# apollo5b register map
Vendor: Ambiq Micro; Series: Apollo; File version: 1.0
CPU: CM55 r1p1, little endian, MPU, FPU, double-precision FPU, DSP, I-cache, D-cache, VTOR, ITCM, DTCM, 4 interrupt priority bits, 0 interrupts, 8 SAU regions
Registers are 32-bit, read-write, reset 0x0 unless marked. A register's access mark holds for its fields unless they carry their own. Offsets are from the block's base; [hi:lo] are bit positions; {n}, {i} and the like mark numbered series; 'fields as' and 'values as' point back to an identical list.

## MSPI0 — Multi-bit SPI Master
Base 0x40060000
Same registers: MSPI1 0x40061000, MSPI2 0x40062000, MSPI3 0x40063000
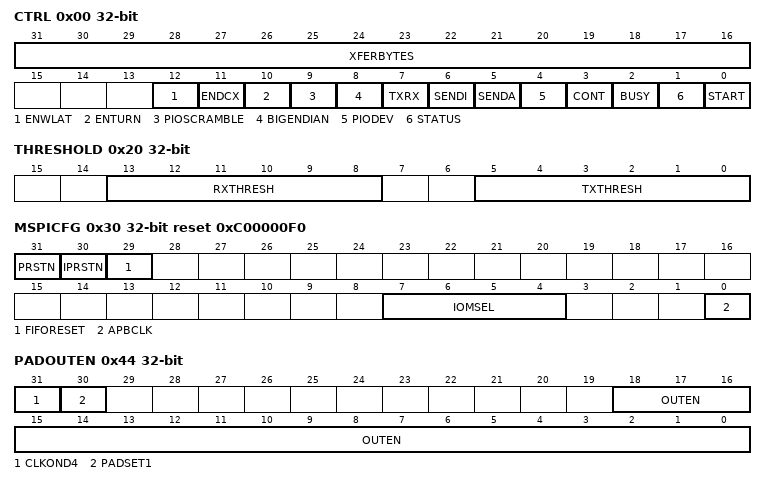
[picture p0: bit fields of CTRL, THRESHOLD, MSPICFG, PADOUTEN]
0x00 CTRL — This register is used to enable individual PIO based transactions to a device on the bus. The CFG register must be programmed properly for the transfer, and the ADDR and INSTR registers should be programmed if the SENDI and SENDA fields are enabled.
  [31:16] XFERBYTES — Number of bytes to transmit or receive (based on TXRX bit)
  [12] ENWLAT — Enable Write Latency Counter (time between address and first data byte). Counter value is WRITELATENCY.
  [11] ENDCX — Enable DCX signal on data [1]
  [10] ENTURN — Indicates whether TX->RX turnaround cycles should be enabled for this operation (see TURNAROUND field in CFG register).
  [9] PIOSCRAMBLE — Enables data scrambling for PIO opertions. This should only be used for data operations and never for commands to a device.
  [8] BIGENDIAN — 1 indicates data in FIFO is in big endian format (MSB first); 0 indicates little endian data (default, LSB first).
  [7] TXRX — 1 Indicates a TX operation, 0 indicates an RX operation of XFERBYTES
  [6] SENDI — Indicates whether an instruction phase should be sent (see INSTR field and ISIZE field in CFG register)
  [5] SENDA — Indicates whether an address phase should be sent (see ADDR register and ASIZE field in CFG register)
  [4] PIODEV — Selects the Device configutation to use for PIO requests
    0=DEVICE0 (Use DEVICE0 Configuration); 1=DEVICE1 (Use DEVICE1 CONFIGURATION)
  [3] CONT — Continuation transfer. When 1, indicates that the MSPI will hold CE low after the transaction completes. This is included for compatibility with IOM module since the MSPI transfer module can handle most cases in a single transfer. NOTE: CONT functionality only works with CLKDIV=2 (24 MHz).
  [2] BUSY — Command status: 1 indicates controller is busy (command in progress)
  [1] STATUS — Command status: 1 indicates command has completed. Cleared by writing 1 to this bit or starting a new transfer.
  [0] START — Write to 1 to initiate a PIO transaction on the bus (typically the entire register should be written at once with this bit set).
0x04 CTRL1 — These registers are used to enable individual PIO based transactions to a device on the bus. The CFG register must be programmed properly for the transfer, and the ADDR and INSTR registers should be programmed if the SENDI and SENDA fields are enabled.
  [3:0] PIOMIXED — Provides override controls for data operations where instruction, address, and data may transfer in different rates.
    0=NORMAL (Transfers all proceed using the settings in DEVCFG register (everything in the same data rate)); 1=D2 (Data operations proceed in dual data rate); 3=AD2 (Address and Data operations proceed in dual data rate); 5=D4 (Data operations proceed in quad data rate); 7=AD4 (Address and Data operations proceed in quad data rate); 9=D8 (Data operations proceed in octal data rate); 11=AD8 (Address and Data operations proceed in octal data rate)
0x08 ADDR — Optional Address field to send for PIO transfers
  [31:0] ADDR — Optional Address field to send (after optional instruction field) - qualified by ASIZE in CMD register. NOTE: This register is aliased to DMADEVADDR.
0x0C INSTR — Optional Instruction field to send for PIO transfers
  [15:0] INSTR — Optional Instruction field to send (1st byte) - qualified by ISEND/ISIZE
0x10 TXFIFO — TX Data FIFO
  [31:0] TXFIFO — Data to be transmitted. Data should normally be aligned to the LSB (pad the upper bits with zeros) unless BIGENDIAN is set.
0x14 RXFIFO — RX Data FIFO
  [31:0] RXFIFO — Receive data. Data is aligned to the LSB (padded zeros on upper bits) unless BIGENDIAN is set.
0x18 TXENTRIES — Number of words in TX FIFO
  [5:0] TXENTRIES — Number of 32-bit words/entries in TX FIFO
0x1C RXENTRIES — Number of words in RX FIFO
  [5:0] RXENTRIES — Number of 32-bit words/entries in RX FIFO
0x20 THRESHOLD — Threshold levels that trigger RXFull and TXEmpty interrupts
  [13:8] RXTHRESH — Number of entries in TX FIFO that cause RXE interrupt
  [5:0] TXTHRESH — Number of entries in TX FIFO that cause TXF interrupt
0x30 MSPICFG reset 0xC00000F0 — Timing configuration bits for the MSPI module. PRSTN, IPRSTN, and FIFORESET can be used to reset portions of the MSPI interface in order to clear error conditions. The remaining bits control clock frequency and TX/RX capture timings.
  [31] PRSTN — Peripheral reset. Master reset to the entire MSPI module (DMA, XIP, and transfer state machines). 1=normal operation, 0=in reset.
  [30] IPRSTN — IP block reset. Write to 0 to put the transfer module in reset or 1 for normal operation. This may be required after error conditions to clear the transfer on the bus.
  [29] FIFORESET — Reset MSPI FIFO (active high). 1=reset FIFO, 0=normal operation. May be used to manually flush the FIFO in error handling.
  [7:4] IOMSEL — Selects which IOM is selected for CQ handshake status.
    {v}=IOM{v} (ERROR: desc VALUE MISSING) (v=0..7); {v}=MSPI{v-8} (ERROR: desc VALUE MISSING) (v=8..11); 15=DISABLED (No IOM selected. Signals always zero.)
  [0] APBCLK — Enable continuous APB clock. For power-efficient operation, APBCLK should be set to 0.
    0=DIS (Disable continuous clock.); 1=EN (Enable continuous clock.)
0x44 PADOUTEN — Enable bits for the MSPI output pads. Each active MSPI line should be set to 1 in the OUTEN field below.
  [31] CLKOND4 — Output clock on MSPI data[4]
  [30] PADSET1 — Only applicable on mspi1. When set, use gpio95 .. gpio 104 as the pads. This extra set of pads is to run mspi0 on HEX and mspi1 concurrently. Note that the timing of this extra pads may not be as good as the origianl pads.
  [18:0] OUTEN — Output pad enable configuration. Indicates which pads should be driven. Bits [3:0] are Quad0 data. Bits [7:4] are Quad1 data. Bit [8] is clock. Bit [9] is BM/DQS. Bit [10:17] are data for 16-bit. Bit[18] is BM/DQS for 16-bit.
    0x10F=QUAD0 (Quad0 (4 data + 1 clock)); 0x1F0=QUAD1 (Quad1 (4 data + 1 clock)); 0x3FF=OCTAL (Octal (8 data + 1 clock)); 0x103=SERIAL0 (Serial (2 data + 1 clock)); 0x130=SERIAL1 (Serial (2 data + 1 clock)); 0x7FFFF=HEX (Octal (16 data + 1 clock + 2 bytemask))
0x48 PADOVEREN — Enables PIO-like pad override control
  [18:0] OVERRIDEEN — Output pad override enable. Bit mask for pad outputs. When set to 1, the values in the OVERRIDE field are driven on the pad (output enable is implicitly set in this mode). [7:0]=data[7:0] [8]=clock [9]=DM [18:11]=data[15:8]
0x4C PADOVER — Override data value
  [18:0] OVERRIDE — Output pad override value. [7:0]=data [8]=clock [9]=DM
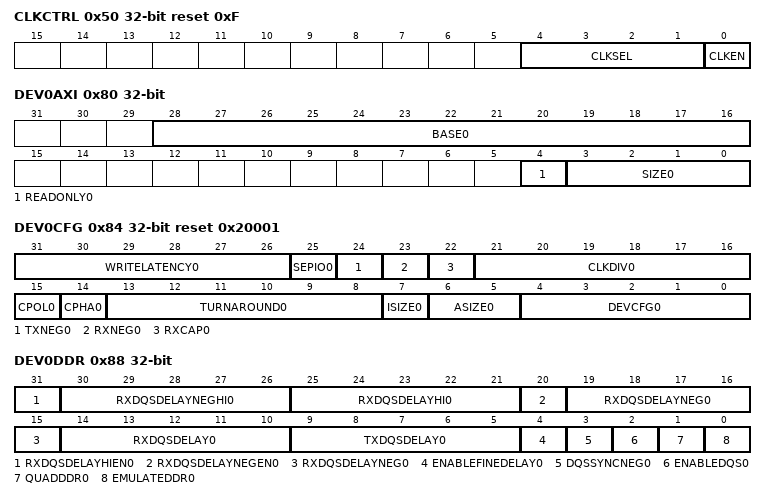
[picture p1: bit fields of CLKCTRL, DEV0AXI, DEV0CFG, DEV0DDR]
0x50 CLKCTRL reset 0xF — Clock control
  [4:1] CLKSEL — MSPI io Clock select
    0=HFRC_750KHz (750KHz sourced from the HFRC); 1=HFRC_1p5MHz (1.5MHz sourced from the HFRC); 2=HFRC_3MHz (3MHz sourced from the HFRC); 3=HFRC_6MHz (6MHz sourced from the HFRC); 4=HFRC_12MHz (12MHz sourced from the HFRC); 5=HFRC_24MHz (24MHz sourced from the HFRC); 6=HFRC_48MHz (48MHz sourced from the HFRC); 7=HFRC_96MHz (96MHz sourced from the HFRC); 8=HFRC_192MHz (192MHz sourced from the HFRC); 9=HFRC2_125MHz (125MHz sourced from the HFRC2); 10=HFRC2_250MHz (250MHz sourced from the HFRC2)
  [0] CLKEN — MSPI io Clock enable.
    0=DIS (Disable mspi io clock); 1=EN (Enable mspi io clock)
0x80 DEV0AXI — Specifies the base address and aperture range of the device as mapped onto the AXI bus
  [28:16] BASE0 — XIPEN has to be enabled to enable aperture. The BASE address needs to be SIZE aligned.
  [4] READONLY0 — Indicates the AXI aperture is read-only
    1=READONLY (Indicates AXI aperture only supports read operations); 0=READWRITE (Indicates AXI aperture supports read and write operations)
  [3:0] SIZE0 — Indicates the AXI aperture size
    0=SIZE64K (64KB Aperture); 1=SIZE128K (128KB Aperture); 2=SIZE256K (256KB Aperture); 3=SIZE512K (512KB Aperture); 4=SIZE1M (1MB Aperture); 5=SIZE2M (2MB Aperture); 6=SIZE4M (4MB Aperture); 7=SIZE8M (8MB Aperture); 8=SIZE16M (16MB Aperture); 9=SIZE32M (32MB Aperture); 10=SIZE64M (64MB Aperture); 11=SIZE128M (128MB Aperture); 12=SIZE256M (256MB Aperture); 13=SIZE512M (512MB Aperture)
0x84 DEV0CFG reset 0x20001 — Command formatting for PIO based transactions (initiated by writes to CTRL register)
  [31:26] WRITELATENCY0 — Number of write Latency cycles. Qualified by ENTURN bit field.
  [25] SEPIO0 — Separate IO configuration. This bit should be set when the target device has separate MOSI and MISO pins. Respective IN/OUT bits below should be set to map pins.
  [24] TXNEG0 — Launches TX data a half clock cycle (~10ns) early. This should normally be programmed to zero (NORMAL).
    0=NORMAL (TX launched from posedge internal clock); 1=NEGEDGE (TX data launched from negedge of internal clock)
  [23] RXNEG0 — Adjusts the RX capture phase to the negedge of the 48MHz internal clock (~10ns early). For normal operation, it is expected that RXNEG will be set to 0.
    0=NORMAL (RX data sampled on posedge of internal clock); 1=NEGEDGE (RX data sampled on negedge of internal clock)
  [22] RXCAP0 — Controls RX data capture phase. A setting of 0 (NORMAL) captures read data at the normal capture point relative to the internal clock launch point. However, to accomodate chip/pad/board delays, a setting of RXCAP of 1 is expected to be used to align the capture point with the return data window. This bit is used in conjunction with RXNEG to provide 4 unique capture points, all about 10ns apart.
    0=NORMAL (RX Capture phase aligns with CPHA setting); 1=DELAY (RX Capture phase is delayed from CPHA setting by one clock edge)
  [21:16] CLKDIV0 — Clock Divider. Allows dividing main MSPI core clock (125MHz/96MHz) by integer multiples. Enumerations are provided for common frequency, but any integer divide from 96 MHz is allowed. Odd divide ratios will result in a 33/66 percent duty cycle with a long low clock pulse (to allow longer round-trip for read data).
    {v}=CLKDIV{v} (Core Clock dividied by {v}) (v=1..4); 6=CLKDIV6 (Core Clock dividied by 6); 8=CLKDIV8 (Core Clock dividied by 8); 12=CLKDIV12 (Core Clock dividied by 12); 16=CLKDIV16 (Core Clock dividied by 16); 24=CLKDIV24 (Core Clock dividied by 24); 32=CLKDIV32 (Core Clock dividied by 32)
  [15] CPOL0 — Serial clock polarity.
    0=LOW (Clock inactive state is low.); 1=HIGH (Clock inactive state is high.)
  [14] CPHA0 — Serial clock phase.
    0=MIDDLE (Clock toggles in middle of data bit.); 1=START (Clock toggles at start of data bit.)
  [13:8] TURNAROUND0 — Number of turnaound cycles (for TX->RX transitions). Qualified by ENTURN bit field.
  [7] ISIZE0 — Instruction Size
    0=I8 (Instruction is 1 byte); 1=I16 (Instruction is 2 bytes)
  [6:5] ASIZE0 — Address Size. Address bytes to send from ADDR register
    0=A1 (Send one address byte); 1=A2 (Send two address bytes); 2=A3 (Send three address bytes); 3=A4 (Send four address bytes)
  [4:0] DEVCFG0 — Flash configuration for XIP and AUTO DMA operations. Controls value for SER (Slave Enable) for XIP operations and address generation for DMA/XIP modes. Also used to configure SPIFRF (frame format).
    1=SERIAL0 (Single bit SPI flash on chip select 0); 2=SERIAL1 (Single bit SPI flash on chip select 1); 5=DUAL0 (Dual SPI flash on chip select 0); 6=DUAL1 (Dual bit SPI flash on chip select 1); 9=QUAD0 (Quad SPI flash on chip select 0); 10=QUAD1 (Quad SPI flash on chip select 1); 13=OCTAL0 (Octal SPI flash on chip select 0); 14=OCTAL1 (Octal SPI flash on chip select 1); 15=QUADPAIRED (Dual Quad SPI flash on chip selects 0/1.); 3=QUADPAIRED_SERIAL (Dual Quad SPI flash on chip selects 0/1, but transmit in serial mode for initialization operations); 17=HEX0 (Hex SPI flash on chip selects 0.); 18=HEX1 (Hex SPI flash on chip selects 1.)
0x88 DEV0DDR — Timing configuration bits for DDR operation of the MSPI module.
  [31] RXDQSDELAYHIEN0 — When 1, RXDQSDELAYHI and RXDQSDELAYNEGHI is used for falling edge of the clock.
  [30:26] RXDQSDELAYNEGHI0 — This acts as an offset to the computed value (should be set to 0 by default) of falling edge for 2nd DQS on HEX mode.
  [25:21] RXDQSDELAYHI0 — This acts as an offset to the computed value (should be set to 0 by default) for 2nd DQS on HEX mode.
  [20] RXDQSDELAYNEGEN0 — When 1, RXDQSDELAYNEG is used for falling edge of the clock.
  [19:15] RXDQSDELAYNEG0 — This acts as an offset to the computed value (should be set to 0 by default) of falling edge.
  [14:10] RXDQSDELAY0 — This acts as an offset to the computed value (should be set to 0 by default)
  [9:5] TXDQSDELAY0 — This acts as an offset to the computed value (should be set to 0 by default)
  [4] ENABLEFINEDELAY0 — Enables use of delay line to provide fine control over traditional RX capture clock.
  [3] DQSSYNCNEG0 — Use negative edge of clock for DDR data sync
  [2] ENABLEDQS0 — In EMULATEDDR mode, enable DQS for read capture
  [1] QUADDDR0 — Deprecated. No effect on RevC.
  [0] EMULATEDDR0 — Drive external clock at 1/2 rate to emulate DDR mode
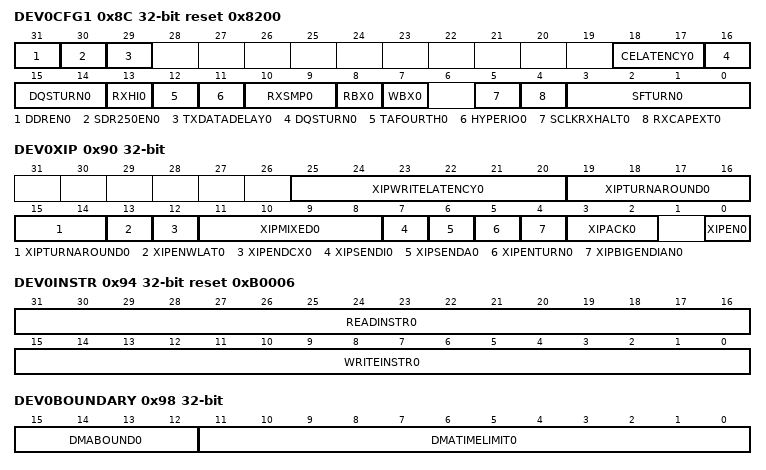
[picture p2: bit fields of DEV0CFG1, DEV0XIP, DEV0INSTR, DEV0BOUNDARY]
0x8C DEV0CFG1 reset 0x8200 — Timing and mode configuration bits for the MSPI module.
  [31] DDREN0 — New DDR mode/logic enable
  [30] SDR250EN0 — Enable MSPI core logic to run at the same frequency as its input clock. This bit has no effect when DDREN is 1
  [29] TXDATADELAY0 — Delay TXDATA output by 1 clock cycle
  [18:17] CELATENCY0 — Mem CE assertion latency before the first Mem transfer clock
    0=NORMAL (1 clock cycle before first mem transfer clock); 1=ADD1 (2 clock cycles before first mem transfer clock); 2=ADD2 (3 clock cycles before first mem transfer clock); 3=ADD3 (4 clock cycles before first mem transfer clock)
  [16:14] DQSTURN0 — In DQS mode, the internal cycle count to enable DQS path.
  [13] RXHI0 — Force st_rx to start at clock high of mspi_clk
  [12] TAFOURTH0 — Add 1/4th mspi_clk in DDR to turnaround. Recommended set this to 1 when EMULATEDDR is set in non-DQS mode (ENABLEDQS = 0).
  [11] HYPERIO0 — When using Windbond, set this bit to 1 to generate CA[47:0] in hardware.
  [10:9] RXSMP0 — Sampling edge based on sclk edge. No effect when div1
  [8] RBX0 — Enable the support of RBX ( page boundary crossing on read )
  [7] WBX0 — Enable the support of WBX ( page boundary crossing on write )
  [5] SCLKRXHALT0 — Halt sclk based on xfer_count
  [4] RXCAPEXT0 — Specify the number of apb_clk of RX capture phse {RXCAPEXT, RXCAP}
  [3:0] SFTURN0 — Subtract from internal counter of write latency and turnaround
0x90 DEV0XIP — When any SPI flash is configured, this register must be properly programmed before XIP or AUTO DMA operations commence.
  [25:20] XIPWRITELATENCY0 — Number of write Latency cycles. Qualified by XIPENWLAT bit field.
  [19:14] XIPTURNAROUND0 — Number of turnaound cycles (for TX->RX transitions). Qualified by XIPENTURN bit field.
  [13] XIPENWLAT0 — Enable Write Latency counter for XIP write transactions
  [12] XIPENDCX0 — Enable DCX signal on data [1] for XIP/DMA operations
  [11:8] XIPMIXED0 — Provides override controls for data operations where instruction, address, and data may transfer in different rates.
    values as CTRL1.PIOMIXED
  [7] XIPSENDI0 — Indicates whether XIP/AUTO DMA operations should send an instruction (see READINSTR field and ISIZE field in CFG)
  [6] XIPSENDA0 — Indicates whether XIP/AUTO DMA operations should send an an address phase (see DMADEVADDR register and ASIZE field in CFG)
  [5] XIPENTURN0 — Indicates whether XIP/AUTO DMA operations should enable TX->RX turnaround cycles
  [4] XIPBIGENDIAN0 — Indicates whether XIP/AUTO DMA data transfers are in big or little endian format
  [3:2] XIPACK0 — Controls transmission of Micron XIP acknowledge cycles (Micron Flash devices only)
    0=NOACK (No acknowledege sent. Data IOs are tristated the first turnaround cycle); 2=ACK (Positive acknowledege sent. Data IOs are driven to 0 the first turnaround cycle to acknowledge XIP mode); 3=TERMINATE (Negative acknowledege sent. Data IOs are driven to 1 the first turnaround cycle to terminate XIP mode. XIPSENDI should be reenabled for the next transfer)
  [0] XIPEN0 — Enable the XIP (eXecute In Place) function which effectively enables the address decoding of the MSPI device in the flash/cache address space at address 0x04000000-0x07FFFFFF.
0x94 DEV0INSTR reset 0xB0006 — When any SPI flash is configured, this register must be properly programmed before XIP or AUTO DMA operations commence.
  [31:16] READINSTR0 — Read command sent to flash for DMA/XIP operations
  [15:0] WRITEINSTR0 — Write command sent for DMA operations
0x98 DEV0BOUNDARY — Allows large transfers to be broken up into smaller ones in hardware to accommodate needs of external devices and allow XIP/XIPMM. Only applicable for memory-mapped devices (PSRAM, Flash, etc) where address can be retransmitted without side effects.
  [15:12] DMABOUND0 — DMA Address boundary
    0=NONE (Disable DMA address boundary breaks); 1=BREAK32 (Break at 32 byte boundary (0x20 increments)); 2=BREAK64 (Break at 64 byte boundary (0x40 increments)); 3=BREAK128 (Break at 128 byte boundary (0x80 increments)); 4=BREAK256 (Break at 256 byte boundary (0x100 increments)); 5=BREAK512 (Break at 512 byte boundary (0x200 increments)); 6=BREAK1K (Break at 1KB boundary (0x400 increments)); 7=BREAK2K (Break at 2KB boundary (0x800 increments)); 8=BREAK4K (Break at 4KB boundary (0x1000 increments)); 9=BREAK8K (Break at 8KB boundary (0x2000 increments)); 10=BREAK16K (Break at 16KB boundary (0x4000 increments))
  [11:0] DMATIMELIMIT0 — DMA time limit. Can be used to limit the transaction time on the MSPI bus. The count is in ~100 ns increments for the 96 MHz clock input. A value of 0 disables the counter.
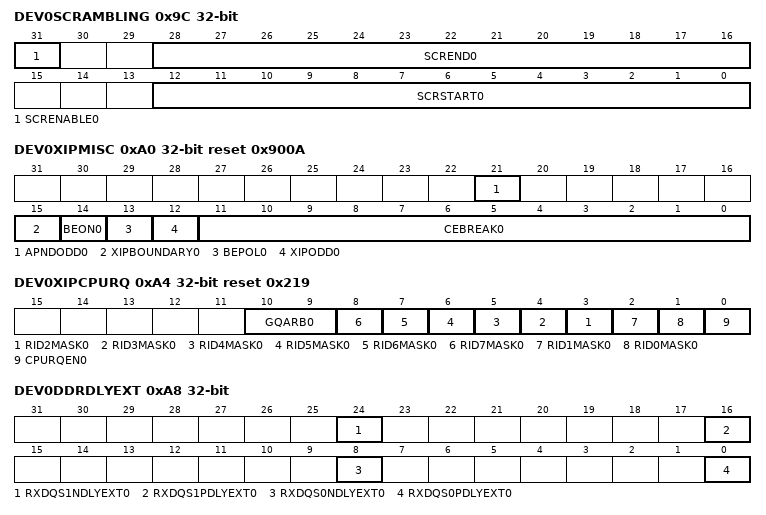
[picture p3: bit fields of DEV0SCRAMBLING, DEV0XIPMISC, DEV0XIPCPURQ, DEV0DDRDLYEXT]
0x9C DEV0SCRAMBLING — Enables data scrambling for the specified range external flash addresses. Scrambling does not impact flash access performance.
  [31] SCRENABLE0 — Enables Data Scrambling Region. When 1 reads and writes to the range will be scrambled. When 0, data will be read/written unmodified. Address range is specified in 64K granularity and the START/END ranges are included within the range.
  [28:16] SCREND0 — Scrambling region end address [28:16] (64K block granularity). The END block is the LAST block included in the scrambled address range.
  [12:0] SCRSTART0 — Scrambling region start address [28:16] (64K block granularity). The START block is the FIRST block included in the scrambled address range.
0xA0 DEV0XIPMISC reset 0x900A — Miscellaneous XIP control registers for AXI logic
  [21] APNDODD0 — Append dummy byte to odd number of write
    0=DIS (No appending byte); 1=EN (Append one dummy byte)
  [15] XIPBOUNDARY0 — Deprecated. No effect on RevC.
    0=DIS (ERROR: desc VALUE MISSING); 1=EN (ERROR: desc VALUE MISSING)
  [14] BEON0 — Byte enable always on for all lanes
    0=DIS (Byte enable is calculated on the fly); 1=EN (Byte enable of all bytes are always on)
  [13] BEPOL0 — byte mask polarity to MSPI xfer
  [12] XIPODD0 — Convert odd starting address to word-aligned starting address with byte-enables for holes. For example, an AXI transaction with wstrb of 0x0600 results in mspi transaction of addr=8 and BE=0b1001 ( active low ).
    0=DIS (No conversion); 1=EN (Enable the conversion)
  [11:0] CEBREAK0 — Number of clock cycles for CE deassertion time
0xA4 DEV0XIPCPURQ reset 0x219 — XIP CPU Read Queue Configuration for AXI logic
  [10:9] GQARB0 — Arbitration Bias between General (Non-CPU) and CPU Rd Queue
    0=B0 (1:1 Simple round robin access grant); 1=B1 (2:1 access grant to General:CPU queue); 2=B2 (3:1 access grant to General:CPU queue); 3=B3 (4:1 access grant to General:CPU queue)
  [n+1] RID{n}MASK0 (n=2..7) — CPU Read ID {n} will in included in CPU Read Queue (if CPURQEN=1)
  [2] RID1MASK0 — CPU Read ID 1 will in included in CPU Read Queue (if CPURQEN=1) (Invalid for CM55 system)
  [1] RID0MASK0 — CPU Read ID 0 will in included in CPU Read Queue (if CPURQEN=1) (Invalid for CM55 system)
  [0] CPURQEN0 — Enable CPU Read Queue
    0=DIS (CPU Read Queue is disabled); 1=EN (CPU Read Queue is enabled)
0xA8 DEV0DDRDLYEXT — DDR RX DQS Delayline MSB bits extenstion for DEV0DDR
  [24] RXDQS1NDLYEXT0 — MSB extension to DEV0DDR.RXDQSDELAYNEGHI0
  [16] RXDQS1PDLYEXT0 — MSB extension to DEV0DDR.RXDQSDELAYHI0
  [8] RXDQS0NDLYEXT0 — MSB extension to DEV0DDR.RXDQSDELAYNEG0
  [0] RXDQS0PDLYEXT0 — MSB extension to DEV0DDR.RXDQSDELAY0
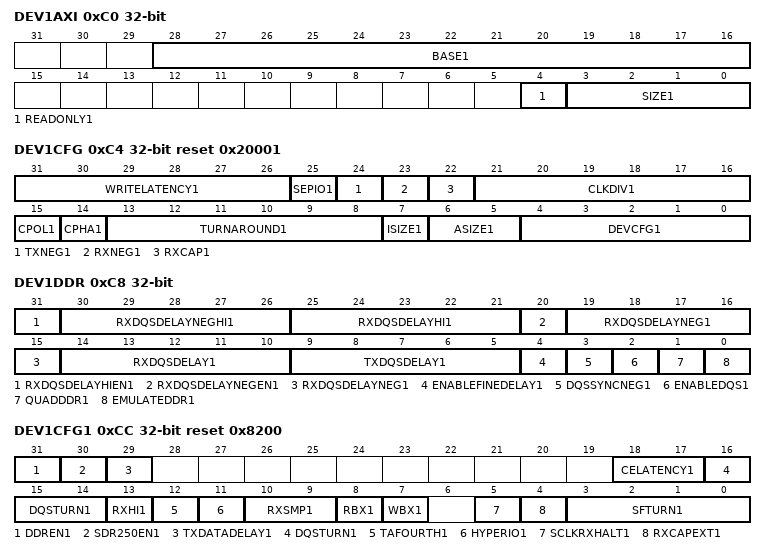
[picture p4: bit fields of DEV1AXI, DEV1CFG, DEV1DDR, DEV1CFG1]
0xC0 DEV1AXI — Specifies the base address and aperture range of the device as mapped onto the AXI bus
  [28:16] BASE1 — XIPEN has to be enabled to enable aperture. The BASE address needs to be SIZE aligned.
  [4] READONLY1 — Indicates the AXI aperture is read-only
    values as DEV0AXI.READONLY0
  [3:0] SIZE1 — Indicates the AXI aperture size
    values as DEV0AXI.SIZE0
0xC4 DEV1CFG reset 0x20001 — Command formatting for PIO based transactions (initiated by writes to CTRL register)
  [31:26] WRITELATENCY1 — Number of write Latency cycles. Qualified by ENTURN bit field.
  [25] SEPIO1 — Separate IO configuration. This bit should be set when the target device has separate MOSI and MISO pins. Respective IN/OUT bits below should be set to map pins.
  [24] TXNEG1 — Launches TX data a half clock cycle (~10ns) early. This should normally be programmed to zero (NORMAL).
    values as DEV0CFG.TXNEG0
  [23] RXNEG1 — Adjusts the RX capture phase to the negedge of the 48MHz internal clock (~10ns early). For normal operation, it is expected that RXNEG will be set to 0.
    values as DEV0CFG.RXNEG0
  [22] RXCAP1 — Controls RX data capture phase. A setting of 0 (NORMAL) captures read data at the normal capture point relative to the internal clock launch point. However, to accomodate chip/pad/board delays, a setting of RXCAP of 1 is expected to be used to align the capture point with the return data window. This bit is used in conjunction with RXNEG to provide 4 unique capture points, all about 10ns apart.
    values as DEV0CFG.RXCAP0
  [21:16] CLKDIV1 — Clock Divider. Allows dividing main MSPI core clock (125MHz/96MHz) by integer multiples. Enumerations are provided for common frequency, but any integer divide from 96 MHz is allowed. Odd divide ratios will result in a 33/66 percent duty cycle with a long low clock pulse (to allow longer round-trip for read data).
    {v}=CLKDIV{v} (Core Clock dividied by {v}) (v=1..4); 6=CLKDIV6 (Core Clock dividied by 6); 8=CLKDIV8 (Core Clock dividied by 8); 12=Core Clock dividied by 12; 16=Core Clock dividied by 16; 24=CLKDIV24 (Core Clock dividied by 24); 32=CLKDIV32 (Core Clock dividied by 32)
  [15] CPOL1 — Serial clock polarity.
    values as DEV0CFG.CPOL0
  [14] CPHA1 — Serial clock phase.
    values as DEV0CFG.CPHA0
  [13:8] TURNAROUND1 — Number of turnaound cycles (for TX->RX transitions). Qualified by ENTURN bit field.
  [7] ISIZE1 — Instruction Size
    0=I8 (Instruction is 1 byte); 1=I16 (Instruction is 2 bytes)
  [6:5] ASIZE1 — Address Size. Address bytes to send from ADDR register
    values as DEV0CFG.ASIZE0
  [4:0] DEVCFG1 — Flash configuration for XIP and AUTO DMA operations. Controls value for SER (Slave Enable) for XIP operations and address generation for DMA/XIP modes. Also used to configure SPIFRF (frame format).
    values as DEV0CFG.DEVCFG0
0xC8 DEV1DDR — Timing configuration bits for DDR operation of the MSPI module.
  [31] RXDQSDELAYHIEN1 — When 1, RXDQSDELAYHI and RXDQSDELAYNEGHI is used for falling edge of the clock.
  [30:26] RXDQSDELAYNEGHI1 — This acts as an offset to the computed value (should be set to 0 by default) of falling edge for 2nd DQS on HEX mode.
  [25:21] RXDQSDELAYHI1 — This acts as an offset to the computed value (should be set to 0 by default) for 2nd DQS on HEX mode.
  [20] RXDQSDELAYNEGEN1 — When 1, RXDQSDELAYNEG is used for falling edge of the clock.
  [19:15] RXDQSDELAYNEG1 — This acts as an offset to the computed value (should be set to 0 by default) of falling edge.
  [14:10] RXDQSDELAY1 — This acts as an offset to the computed value (should be set to 0 by default)
  [9:5] TXDQSDELAY1 — This acts as an offset to the computed value (should be set to 0 by default)
  [4] ENABLEFINEDELAY1 — Enables use of delay line to provide fine control over traditional RX capture clock.
  [3] DQSSYNCNEG1 — Use negative edge of clock for DDR data sync
  [2] ENABLEDQS1 — In EMULATEDDR mode, enable DQS for read capture
  [1] QUADDDR1 — Deprecated. No effect on RevC.
  [0] EMULATEDDR1 — Drive external clock at 1/2 rate to emulate DDR mode
0xCC DEV1CFG1 reset 0x8200 — Timing and mode configuration bits for the MSPI module.
  [31] DDREN1 — New DDR mode/logic enable
  [30] SDR250EN1 — Enable MSPI core logic to run at the same frequency as its input clock. This bit has no effect when DDREN is 1
  [29] TXDATADELAY1 — Delay TXDATA output by 1 clock cycle
  [18:17] CELATENCY1 — Mem CE assertion latency before the first Mem transfer clock
    values as DEV0CFG1.CELATENCY0
  [16:14] DQSTURN1 — In DQS mode, the internal cycle count to enable DQS path.
  [13] RXHI1 — Force st_rx to start at clock high of mspi_clk
  [12] TAFOURTH1 — Add 1/4th mspi_clk in DDR to turnaround. Recommended set this to 1 when EMULATEDDR is set in non-DQS mode (ENABLEDQS = 0).
  [11] HYPERIO1 — When using Windbond, set this bit to 1 to generate CA[47:0] in hardware.
  [10:9] RXSMP1 — Sampling edge based on sclk edge. No effect when div1
  [8] RBX1 — Enable the support of RBX ( page boundary crossing on read )
  [7] WBX1 — Enable the support of WBX ( page boundary crossing on write )
  [5] SCLKRXHALT1 — Halt sclk based on xfer_count
  [4] RXCAPEXT1 — Specify the number of apb_clk of RX capture phse {RXCAPEXT, RXCAP}
  [3:0] SFTURN1 — Subtract from internal counter of write latency and turnaround
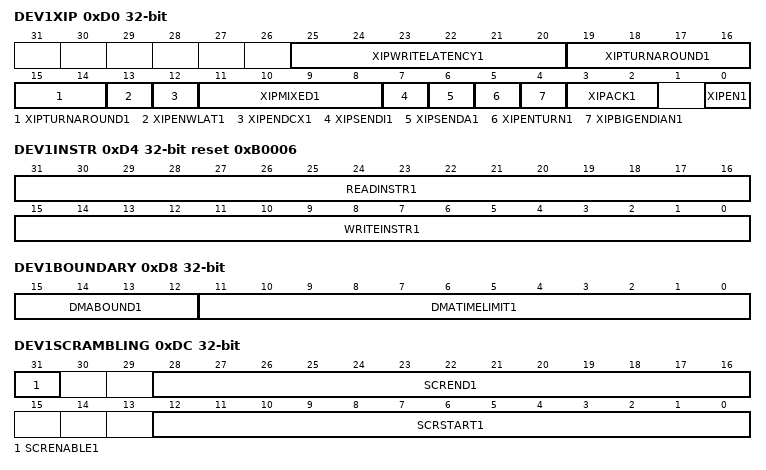
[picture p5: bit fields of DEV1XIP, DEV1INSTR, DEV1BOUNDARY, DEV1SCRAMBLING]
0xD0 DEV1XIP — When any SPI flash is configured, this register must be properly programmed before XIP or AUTO DMA operations commence.
  [25:20] XIPWRITELATENCY1 — Number of write Latency cycles. Qualified by XIPENWLAT bit field.
  [19:14] XIPTURNAROUND1 — Number of turnaound cycles (for TX->RX transitions). Qualified by XIPENTURN bit field.
  [13] XIPENWLAT1 — Enable Write Latency counter for XIP write transactions
  [12] XIPENDCX1 — Enable DCX signal on data [1] for XIP/DMA operations
  [11:8] XIPMIXED1 — Provides override controls for data operations where instruction, address, and data may transfer in different rates.
    values as CTRL1.PIOMIXED
  [7] XIPSENDI1 — Indicates whether XIP/AUTO DMA operations should send an instruction (see READINSTR field and ISIZE field in CFG)
  [6] XIPSENDA1 — Indicates whether XIP/AUTO DMA operations should send an an address phase (see DMADEVADDR register and ASIZE field in CFG)
  [5] XIPENTURN1 — Indicates whether XIP/AUTO DMA operations should enable TX->RX turnaround cycles
  [4] XIPBIGENDIAN1 — Indicates whether XIP/AUTO DMA data transfers are in big or little endian format
  [3:2] XIPACK1 — Controls transmission of Micron XIP acknowledge cycles (Micron Flash devices only)
    values as DEV0XIP.XIPACK0
  [0] XIPEN1 — Enable the XIP (eXecute In Place) function which effectively enables the address decoding of the MSPI device in the flash/cache address space at address 0x04000000-0x07FFFFFF.
0xD4 DEV1INSTR reset 0xB0006 — When any SPI flash is configured, this register must be properly programmed before XIP or AUTO DMA operations commence.
  [31:16] READINSTR1 — Read command sent to flash for DMA/XIP operations
  [15:0] WRITEINSTR1 — Write command sent for DMA operations
0xD8 DEV1BOUNDARY — Allows large transfers to be broken up into smaller ones in hardware to accommodate needs of external devices and allow XIP/XIPMM. Only applicable for memory-mapped devices (PSRAM, Flash, etc) where address can be retransmitted without side effects.
  [15:12] DMABOUND1 — DMA Address boundary
    values as DEV0BOUNDARY.DMABOUND0
  [11:0] DMATIMELIMIT1 — DMA time limit. Can be used to limit the transaction time on the MSPI bus. The count is in ~100 ns increments for the 96 MHz clock input. A value of 0 disables the counter.
0xDC DEV1SCRAMBLING — Enables data scrambling for the specified range external flash addresses. Scrambling does not impact flash access performance.
  [31] SCRENABLE1 — Enables Data Scrambling Region. When 1 reads and writes to the range will be scrambled. When 0, data will be read/written unmodified. Address range is specified in 64K granularity and the START/END ranges are included within the range.
  [28:16] SCREND1 — Scrambling region end address [28:16] (64K block granularity). The END block is the LAST block included in the scrambled address range.
  [12:0] SCRSTART1 — Scrambling region start address [28:16] (64K block granularity). The START block is the FIRST block included in the scrambled address range.
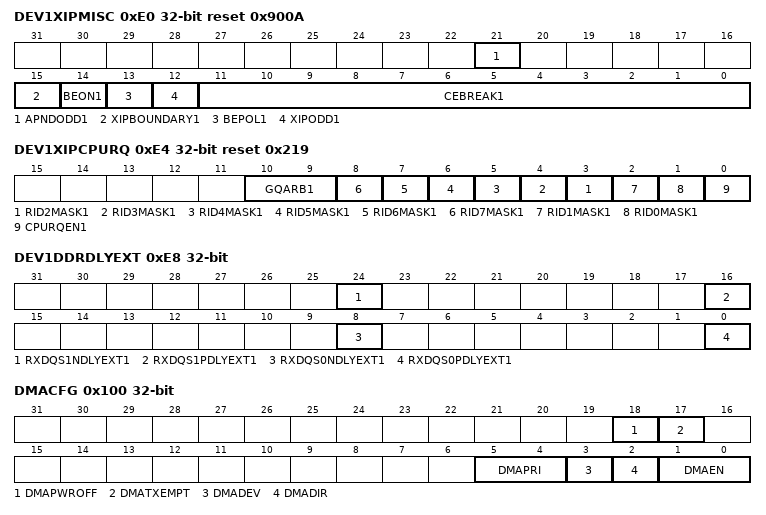
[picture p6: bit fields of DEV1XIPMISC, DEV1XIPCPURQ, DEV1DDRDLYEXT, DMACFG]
0xE0 DEV1XIPMISC reset 0x900A — Miscellaneous XIP control registers for AXI logic
  [21] APNDODD1 — Append dummy byte to odd number of write
    0=DIS (No appending byte); 1=EN (Append one dummy byte)
  [15] XIPBOUNDARY1 — Deprecated. No effect on RevC.
    values as DEV0XIPMISC.XIPBOUNDARY0
  [14] BEON1 — Byte enable always on for all lanes
    values as DEV0XIPMISC.BEON0
  [13] BEPOL1 — byte mask polarity to MSPI xfer
  [12] XIPODD1 — Convert odd starting address to word-aligned starting address with byte-enables for holes. For example, an AXI transaction with wstrb of 0x0600 results in mspi transaction of addr=8 and BE=0b1001 ( active low ).
    0=DIS (No conversion); 1=EN (Enable the conversion)
  [11:0] CEBREAK1 — Number of clock cycles for CE deassertion time
0xE4 DEV1XIPCPURQ reset 0x219 — XIP CPU Read Queue Configuration for AXI logic
  [10:9] GQARB1 — Arbitration Bias between General (Non-CPU) and CPU Rd Queue
    values as DEV0XIPCPURQ.GQARB0
  [n+1] RID{n}MASK1 (n=2..7) — CPU Read ID {n} will in included in CPU Read Queue (if CPURQEN=1)
  [2] RID1MASK1 — CPU Read ID 1 will in included in CPU Read Queue (if CPURQEN=1) (Invalid for CM55 system)
  [1] RID0MASK1 — CPU Read ID 0 will in included in CPU Read Queue (if CPURQEN=1) (Invalid for CM55 system)
  [0] CPURQEN1 — Enable CPU Read Queue
    values as DEV0XIPCPURQ.CPURQEN0
0xE8 DEV1DDRDLYEXT — DDR RX DQS Delayline MSB bits extenstion for DEV1DDR
  [24] RXDQS1NDLYEXT1 — MSB extension to DEV1DDR.RXDQSDELAYNEGHI1
  [16] RXDQS1PDLYEXT1 — MSB extension to DEV1DDR.RXDQSDELAYHI1
  [8] RXDQS0NDLYEXT1 — MSB extension to DEV1DDR.RXDQSDELAYNEG1
  [0] RXDQS0PDLYEXT1 — MSB extension to DEV1DDR.RXDQSDELAY1
0x100 DMACFG — DMA Configuration
  [18] DMAPWROFF — Power off MSPI domain upon completion of DMA operation.
  [17] DMATXEMPT — For DMA_M2P, only start when DMA fifo is not empty.
  [5:4] DMAPRI — Sets the Priority of the DMA request
    0=LOW (Low Priority (service as best effort)); 1=HIGH (High Priority (service immediately)); 2=AUTO (Auto Priority (priority raised once TX FIFO empties or RX FIFO fills))
  [3] DMADEV — DMA Device Select
    0=DEV0 (Select Device 0 for DMA); 1=DEV1 (Select Device 1 for DMA)
  [2] DMADIR — Direction
    0=P2M (Peripheral to Memory (SRAM) transaction); 1=M2P (Memory to Peripheral transaction)
  [1:0] DMAEN — DMA Enable. Setting this bit to EN will start the DMA operation
    0=DIS (Disable DMA Function); 3=EN (Enable HW controlled DMA Function to manage DMA to flash devices. HW will automatically handle issuance of instruction/address bytes based on settings in the FLASH register.)
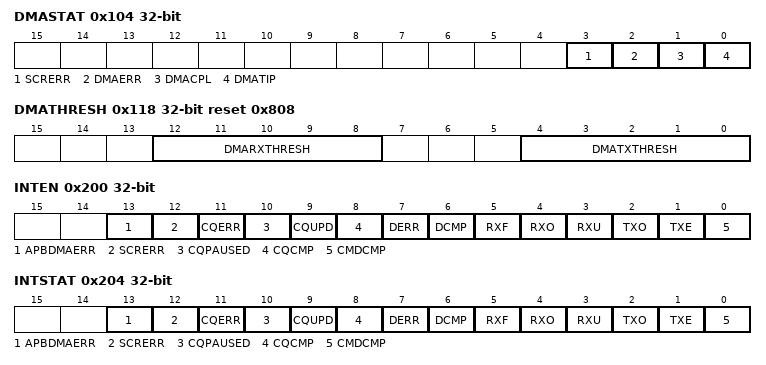
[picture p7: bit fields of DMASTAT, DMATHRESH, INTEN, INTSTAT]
0x104 DMASTAT — DMA Status
  [3] SCRERR — Scrambling Access Alignment Error. This active high bit signals that a scrambling operation was specified for a non-word aligned DEVADDR.
  [2] DMAERR — DMA Error. This active high bit signals that an error was encountered during the DMA operation.
  [1] DMACPL — DMA Transfer Complete. This signals the end of the DMA operation.
  [0] DMATIP — DMA Transfer In Progress indicator. 1 will indicate that a DMA transfer is active. The DMA transfer may be waiting on data, transferring data, or waiting for priority. All of these will be indicated with a 1. A 0 will indicate that the DMA is fully complete and no further transactions will be done.
0x108 DMATARGADDR — DMA Target Address
  [31:0] TARGADDR — Target byte address for source of DMA (either read or write). In cases of non-word aligned addresses, the DMA logic will take care for ensuring only the target bytes are read/written.
0x10C DMADEVADDR — DMA Device Address
  [31:0] DEVADDR — SPI Device address for automated DMA transactions (both read and write).
0x110 DMATOTCOUNT — DMA Total Transfer Count
  [23:0] TOTCOUNT — Total Transfer Count in bytes.
0x114 DMABCOUNT reset 0x20 — DMA BYTE Transfer Count
  [7:0] BCOUNT — Burst transfer size in bytes. This is the number of bytes transferred when a FIFO trigger event occurs. Recommended value is 32.
0x118 DMATHRESH reset 0x808 — Indicates FIFO level at which a DMA should be triggered. For most configurations, a setting of 8 is recommended for both read and write operations.
  [12:8] DMARXTHRESH — DMA transfer FIFO level trigger. For read operations, DMA is triggered when the FIFO level is greater than this value. For write operations, DMA is triggered when the FIFO level is less than this level. Each DMA operation will consist of BCOUNT bytes. This value should not be set more than ALTRXFIFOFULL.
  [4:0] DMATXTHRESH — DMA transfer FIFO level trigger. For read operations, DMA is triggered when the FIFO level is greater than this value. For write operations, DMA is triggered when the FIFO level is less than this level. Each DMA operation will consist of BCOUNT bytes.
0x200 INTEN — Set bits in this register to allow this module to generate the corresponding interrupt.
  [13] APBDMAERR — MSPI is dma target as well as dma source, which may result in deadlock.
  [12] SCRERR — Scrambling Alignment Error. Scrambling operations must be aligned to word (4-byte) start address.
  [11] CQERR — Command Queue Error Interrupt
  [10] CQPAUSED — Command Queue is Paused.
  [9] CQUPD — Command Queue Update Interrupt. Issued whenever the CQ performs an operation where address bit[0] is set. Useful for triggering CURIDX interrupts.
  [8] CQCMP — Command Queue Complete Interrupt
  [7] DERR — DMA Error Interrupt
  [6] DCMP — DMA Complete Interrupt
  [5] RXF — Receive FIFO full
  [4] RXO — Receive FIFO overflow (cannot happen in MSPI design -- MSPI bus pins will stall)
  [3] RXU — Receive FIFO underflow (only occurs when SW reads from an empty FIFO)
  [2] TXO — Transmit FIFO Overflow (only occurs when SW writes to a full FIFO).
  [1] TXE — Transmit FIFO empty.
  [0] CMDCMP — Transfer complete. Note that DMA and CQ operations are layered, so CMDCMP, DCMP, and CQ* can all be signaled simultaneously.
0x204 INTSTAT — Read bits from this register to discover the cause of a recent interrupt.
  fields as INTEN
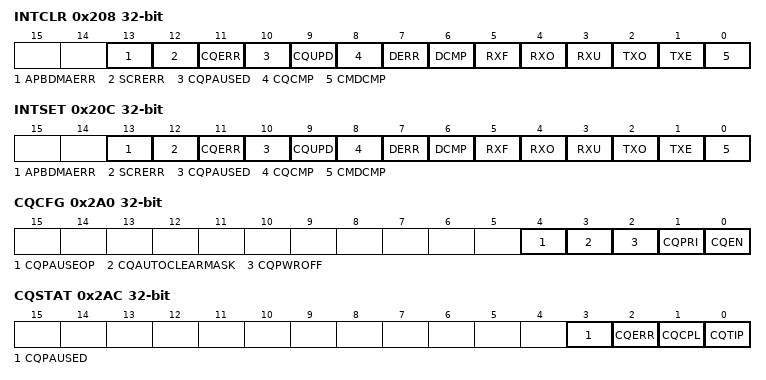
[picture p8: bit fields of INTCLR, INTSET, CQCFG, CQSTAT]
0x208 INTCLR — Write a 1 to a bit in this register to clear the interrupt status associated with that bit.
  fields as INTEN
0x20C INTSET — Write a 1 to a bit in this register to instantly generate an interrupt from this module. (Generally used for testing purposes).
  fields as INTEN
0x2A0 CQCFG — This register controls Command Queuing (CQ) operations in a manner similar to the DMACFG register.
  [4] CQPAUSEOP — To pause Command Queue Operation
  [3] CQAUTOCLEARMASK — Enable clear of CQMASK after each pause operation. This may be useful when using software flags to pause CQ.
  [2] CQPWROFF — Power off MSPI domain upon completion of DMA operation.
  [1] CQPRI — Sets the Priority of the command queue DMA request
    0=LOW (Low Priority (service as best effort)); 1=HIGH (High Priority (service immediately))
  [0] CQEN — Command queue enable. When set, will enable the processing of the command queue
    0=DIS (Disable CQ Function); 1=EN (Enable CQ Function)
0x2A8 CQADDR — Location of the command queue in SRAM or flash memory. This register will increment as CQ operations commence. Software should only write CQADDR when CQEN is disabled, however the command queue script itself may update CQADDR in order to perform queue management functions (like resetting the pointers)
  [31:0] CQADDR — Address of command queue buffer in SRAM or flash. The buffer address must be aligned to a word boundary.
0x2AC CQSTAT — Command Queue Status
  [3] CQPAUSED — Command queue is currently paused status.
  [2] CQERR — Command queue processing Error. This active high bit signals that an error was encountered during the CQ operation.
  [1] CQCPL — Command queue operation Complete. This signals the end of the command queue operation.
  [0] CQTIP — Command queue Transfer In Progress indicator. 1 will indicate that a CQ transfer is active and this will remain active even when paused waiting for external event.
0x2B0 CQFLAGS — Command Queue Flags
  [15:0] CQFLAGS — Current flag status (read-only). Bits [7:0] are software controllable and bits [15:8] are hardware status.
    0x8000=STOP (CQ Stop Flag. When set, CQ processing will complete.); 0x4000=CQIDX (CQ Index Pointers (CURIDX/ENDIDX) match.); 0x2000=BUF1XOREN (Buffer 1 Ready Status (from selected IOM/MSPI). This status is the result of XOR'ing the IOM1START with the incoming status from the IOM. When high, MSPI can transfer the buffer.); 0x1000=BUF0XOREN (Buffer 0 Ready Status (from selected IOM/MSPI). This status is the result of XOR'ing the IOM0START with the incoming status from the IOM. When high, MSPI can transfer the buffer.); 0x800=DMACPL (DMA Complete Status (hardwired DMACPL bit in DMASTAT)); 0x400=CMDCPL (PIO Operation completed (STATUS bit in CTRL register)); 0x200=IOM1READY ((BUF1XNOREN) IOM Buffer 1 Ready Status (from selected IOM). This status is the result of XNOR'ing the IOM0START with the incoming status from the IOM. When high, MSPI can send to the buffer.); 0x100=IOM0READY ((BUF0XNOREN) IOM Buffer 0 Ready Status (from selected IOM). This status is the result of XNOR'ing the IOM0START with the incoming status from the IOM. When high, MSPI can send to the buffer.); 128=SWFLAG7 (Software flag 7. Can be used by software to start/pause operations.); 64=SWFLAG6 (Software flag 6. Can be used by software to start/pause operations.); 32=SWFLAG5 (Software flag 5. Can be used by software to start/pause operations.); 16=SWFLAG4 (Software flag 4. Can be used by software to start/pause operations.); 8=SWFLAG3 (Software flag 3. Can be used by software to start/pause operations.); 4=SWFLAG2 (Software flag 2. Can be used by software to start/pause operations.); 2=SWFLAG1 (Software flag 1. Can be used by software to start/pause operations. Also, IOM Buffer 1 status. When linked to IOM, indicates to IOM that buffer 1 is ready.); 1=SWFLAG0 (Software flag 0. Can be used by software to start/pause operations. Also, IOM Buffer 0 status. When linked to IOM, indicates to IOM that buffer 0 is ready.)
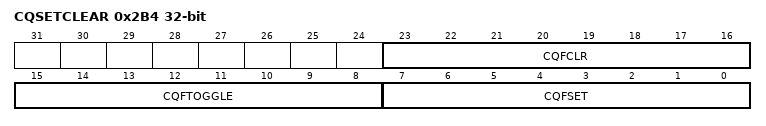
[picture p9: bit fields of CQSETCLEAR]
0x2B4 CQSETCLEAR — Command Queue Flag Set/Clear
  [23:16] CQFCLR — Clear CQFlag status bits.
  [15:8] CQFTOGGLE — Toggle CQFlag status bits
  [7:0] CQFSET — Set CQFlag status bits. Set has priority over clear if both are high.
0x2B8 CQPAUSE — Command Queue Pause Mask
  [15:0] CQMASK — CQ will pause processing when ALL specified events are satisfied -- i.e. when (CQMASK and CQPAUSE)==CQMASK.
    0x8000=STOP (CQ Stop Flag. When set, CQ processing will complete.); 0x4000=CQIDX (CQ Index Pointers (CURIDX/ENDIDX) match.); 0x2000=BUF1XOREN (Buffer 1 Ready Status (from selected IOM/MSPI). This status is the result of XOR'ing the IOM1START with the incoming status from the IOM. When high, MSPI can transfer the buffer.); 0x1000=BUF0XOREN (Buffer 0 Ready Status (from selected IOM/MSPI). This status is the result of XOR'ing the IOM0START with the incoming status from the IOM. When high, MSPI can transfer the buffer.); 0x800=DMACPL (DMA Complete Status (hardwired DMACPL bit in DMASTAT)); 0x400=CMDCPL (PIO Operation completed (STATUS bit in CTRL register)); 0x200=IOM1READY ((BUF1XNOREN) IOM Buffer 1 Ready Status (from selected IOM). This status is the result of XNOR'ing the IOM0START with the incoming status from the IOM. When high, MSPI can send to the buffer.); 0x100=IOM0READY ((BUF0XNOREN) IOM Buffer 0 Ready Status (from selected IOM). This status is the result of XNOR'ing the IOM0START with the incoming status from the IOM. When high, MSPI can send to the buffer.); 128=SWFLAG7 (Software flag 7. Can be used by software to start/pause operations.); 64=SWFLAG6 (Software flag 6. Can be used by software to start/pause operations.); 32=SWFLAG5 (Software flag 5. Can be used by software to start/pause operations.); 16=SWFLAG4 (Software flag 4. Can be used by software to start/pause operations.); 8=SWFLAG3 (Software flag 3. Can be used by software to start/pause operations.); 4=SWFLAG2 (Software flag 2. Can be used by software to start/pause operations.); 2=SWFLAG1 (Software flag 1. Can be used by software to start/pause operations. Also, IOM Buffer 1 status (same as SWFLAG1). When linked to IOM, indicates to IOM that buffer 1 is ready.); 1=SWFLAG0 (Software flag 0. Can be used by software to start/pause operations. Also, IOM Buffer 0 status (same as SWFLAG0). When linked to IOM, indicates to IOM that buffer 0 is ready.)
0x2C0 CQCURIDX — This register can be used in conjunction with the CQENDIDX register to manage the command queue. Typically software will initialize the CQCURIDX and CQENDIDX to the same value, which will cause the CQ to be paused when enabled. Software may then add entries to the command queue (in SRAM) and update CQENDIDX. The command queue operations will then increment CQCURIDX as it processes operations. Once CQCURIDX==CQENDIDX, the command queue hardware will automatically pause since no additional operations have been appended to the queue.
  [7:0] CQCURIDX — Can be used to indicate the current position of the command queue by having CQ operations write this field. A CQ hardware status flag indicates when CURIDX and ENDIDX are not equal, allowing SW to pause the CQ processing until the end index is updated.
0x2C4 CQENDIDX — Command Queue End Index
  [7:0] CQENDIDX — Can be used to indicate the end position of the command queue. A CQ hardware status bit indices when CURIDX != ENDIDX so that the CQ can be paused when it reaches the end pointer.
